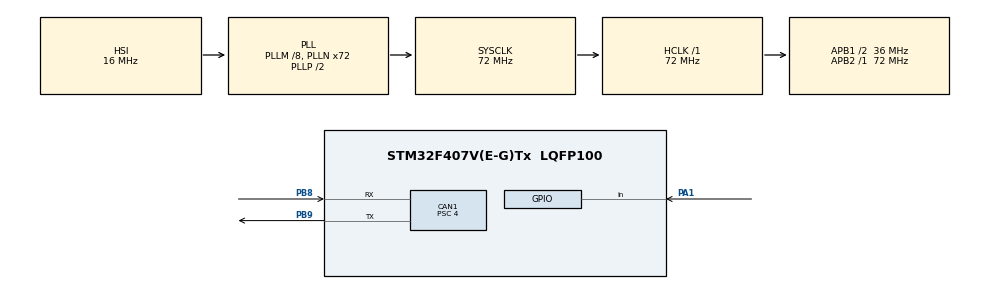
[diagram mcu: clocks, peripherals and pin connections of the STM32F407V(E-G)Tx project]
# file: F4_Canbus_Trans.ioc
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CAN1.BS1=CAN_BS1_15TQ
CAN1.BS2=CAN_BS2_2TQ
CAN1.CalculateBaudRate=500000
CAN1.CalculateTimeBit=2000
CAN1.CalculateTimeQuantum=111.11111111111111
CAN1.Prescaler=4
Mcu.Family=STM32F4
Mcu.Name=STM32F407V(E-G)Tx
Mcu.Package=LQFP100
NVIC.CAN1_RX0_IRQn=true\:1\:0\:true\:false\:true\:true\:true\:true
NVIC.PriorityGroup=NVIC_PRIORITYGROUP_4
PA1.GPIO_PuPd=GPIO_PULLUP
PA1.Signal=GPIO_Input
PA13.Mode=Serial_Wire
PA13.Signal=SYS_JTMS-SWDIO
PA14.Mode=Serial_Wire
PA14.Signal=SYS_JTCK-SWCLK
PB8.GPIO_PuPd=GPIO_PULLUP
PB8.Mode=CAN_Activate
PB8.Signal=CAN1_RX
PB9.Mode=CAN_Activate
PB9.Signal=CAN1_TX
PH0-OSC_IN.Mode=HSE-External-Oscillator
PH0-OSC_IN.Signal=RCC_OSC_IN
PH1-OSC_OUT.Mode=HSE-External-Oscillator
PH1-OSC_OUT.Signal=RCC_OSC_OUT
ProjectManager.HeapSize=0x200
ProjectManager.StackSize=0x400
ProjectManager.TargetToolchain=MDK-ARM V5.32
RCC.48MHZClocksFreq_Value=36000000
RCC.AHBFreq_Value=72000000
RCC.APB1CLKDivider=RCC_HCLK_DIV2
RCC.APB1Freq_Value=36000000
RCC.APB1TimFreq_Value=72000000
RCC.APB2Freq_Value=72000000
RCC.APB2TimFreq_Value=72000000
RCC.CortexFreq_Value=72000000
RCC.HCLKFreq_Value=72000000
RCC.HSE_VALUE=25000000
RCC.HSI_VALUE=16000000
RCC.LSE_VALUE=32768
RCC.PLLM=8
RCC.PLLN=72
RCC.SYSCLKFreq_VALUE=72000000
RCC.SYSCLKSource=RCC_SYSCLKSOURCE_PLLCLK
RCC.VCOOutputFreq_Value=144000000
board=custom

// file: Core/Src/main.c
/* USER CODE BEGIN Header */
/**
  ******************************************************************************
  * @file           : main.c
  * @brief          : Main program body
  ******************************************************************************
  * @attention
  *
  * Copyright (c) 2024 STMicroelectronics.
  * All rights reserved.
  *
  * This software is licensed under terms that can be found in the LICENSE file
  * in the root directory of this software component.
  * If no LICENSE file comes with this software, it is provided AS-IS.
  *
  ******************************************************************************
  */
/* USER CODE END Header */
#include "main.h"

/* USER CODE BEGIN Includes */
#include "Button.h"
#include "Rx.h"
#include "Tx.h"
/* USER CODE END Includes */

CAN_HandleTypeDef hcan1;

/* USER CODE BEGIN PV */
Button_TypeDef Button1;
/* USER CODE END PV */

void SystemClock_Config(void);
static void MX_GPIO_Init(void);
static void MX_CAN1_Init(void);

/* USER CODE BEGIN 0 */
CAN_TxHeaderTypeDef TxHeader;
uint8_t Tx[8];
uint32_t TxMailBox;
uint8_t test=0;
_LedState LedState = LedOff;
void button_press(Button_TypeDef *buttonx)//Ham xu li khi nhan nut
{
	if (buttonx == &Button1 )
	{
		switch(LedState)
		{
			case(LedOff):
				Tx[0]=1;
				LedState = LedBlink;
				break;
			case(LedBlink):
				Tx[0]=0;
				LedState = LedOff;
				break;
			default:
				break;
		}
		HAL_CAN_AddTxMessage(&hcan1,&TxHeader ,Tx,&TxMailBox );
	}
}
/* USER CODE END 0 */

int main(void)
{

  /* MCU Configuration--------------------------------------------------------*/

  /* Reset of all peripherals, Initializes the Flash interface and the Systick. */
  HAL_Init();

  /* Configure the system clock */
  SystemClock_Config();

  /* Initialize all configured peripherals */
  MX_GPIO_Init();
  MX_CAN1_Init();
  /* USER CODE BEGIN 2 */
	button_init(&Button1, GPIOA, GPIO_PIN_1);//Khai bao chan nut bam
	HAL_CAN_Start(&hcan1);
	//Config TxHeader
	TxHeader.DLC = 5;
	TxHeader.IDE = CAN_ID_STD;
	TxHeader.RTR = CAN_RTR_DATA;
	TxHeader.StdId = 0x222;
	TxHeader.TransmitGlobalTime = DISABLE;

	Tx_Data_Led_Blink(Tx,200);

	HAL_CAN_ActivateNotification(&hcan1,CAN_IT_RX_FIFO0_MSG_PENDING);
  /* USER CODE END 2 */

  /* Infinite loop */
  while (1)
  {

    /* USER CODE BEGIN 3 */
		button_handle(&Button1);
  }
  /* USER CODE END 3 */
}

void SystemClock_Config(void)
{
  RCC_OscInitTypeDef RCC_OscInitStruct = {0};
  RCC_ClkInitTypeDef RCC_ClkInitStruct = {0};

  /** Configure the main internal regulator output voltage
  */
  __HAL_RCC_PWR_CLK_ENABLE();
  __HAL_PWR_VOLTAGESCALING_CONFIG(PWR_REGULATOR_VOLTAGE_SCALE1);

  /** Initializes the RCC Oscillators according to the specified parameters
  * in the RCC_OscInitTypeDef structure.
  */
  RCC_OscInitStruct.OscillatorType = RCC_OSCILLATORTYPE_HSI;
  RCC_OscInitStruct.HSIState = RCC_HSI_ON;
  RCC_OscInitStruct.HSICalibrationValue = RCC_HSICALIBRATION_DEFAULT;
  RCC_OscInitStruct.PLL.PLLState = RCC_PLL_ON;
  RCC_OscInitStruct.PLL.PLLSource = RCC_PLLSOURCE_HSI;
  RCC_OscInitStruct.PLL.PLLM = 8;
  RCC_OscInitStruct.PLL.PLLN = 72;
  RCC_OscInitStruct.PLL.PLLP = RCC_PLLP_DIV2;
  RCC_OscInitStruct.PLL.PLLQ = 4;
  if (HAL_RCC_OscConfig(&RCC_OscInitStruct) != HAL_OK)
  {
    Error_Handler();
  }

  /** Initializes the CPU, AHB and APB buses clocks
  */
  RCC_ClkInitStruct.ClockType = RCC_CLOCKTYPE_HCLK|RCC_CLOCKTYPE_SYSCLK
                              |RCC_CLOCKTYPE_PCLK1|RCC_CLOCKTYPE_PCLK2;
  RCC_ClkInitStruct.SYSCLKSource = RCC_SYSCLKSOURCE_PLLCLK;
  RCC_ClkInitStruct.AHBCLKDivider = RCC_SYSCLK_DIV1;
  RCC_ClkInitStruct.APB1CLKDivider = RCC_HCLK_DIV2;
  RCC_ClkInitStruct.APB2CLKDivider = RCC_HCLK_DIV1;

  if (HAL_RCC_ClockConfig(&RCC_ClkInitStruct, FLASH_LATENCY_2) != HAL_OK)
  {
    Error_Handler();
  }
}

static void MX_CAN1_Init(void)
{

  hcan1.Instance = CAN1;
  hcan1.Init.Prescaler = 4;
  hcan1.Init.Mode = CAN_MODE_NORMAL;
  hcan1.Init.SyncJumpWidth = CAN_SJW_1TQ;
  hcan1.Init.TimeSeg1 = CAN_BS1_15TQ;
  hcan1.Init.TimeSeg2 = CAN_BS2_2TQ;
  hcan1.Init.TimeTriggeredMode = DISABLE;
  hcan1.Init.AutoBusOff = DISABLE;
  hcan1.Init.AutoWakeUp = DISABLE;
  hcan1.Init.AutoRetransmission = DISABLE;
  hcan1.Init.ReceiveFifoLocked = DISABLE;
  hcan1.Init.TransmitFifoPriority = DISABLE;
  if (HAL_CAN_Init(&hcan1) != HAL_OK)
  {
    Error_Handler();
  }
  /* USER CODE BEGIN CAN1_Init 2 */
	CAN_FilterTypeDef CanFilter;

	CanFilter.FilterActivation = CAN_FILTER_ENABLE;
	CanFilter.FilterBank = 10;
	CanFilter.FilterFIFOAssignment = CAN_FILTER_FIFO0;
	CanFilter.FilterIdHigh = 0X111<<5;
	CanFilter.FilterIdLow = 0X000000;
	CanFilter.FilterMaskIdHigh = 0X111<<5;
	CanFilter.FilterMaskIdLow = 0X000000;
	CanFilter.FilterMode = CAN_FILTERMODE_IDMASK;
	CanFilter.FilterScale = CAN_FILTERSCALE_32BIT;
	CanFilter.SlaveStartFilterBank = 0;

	HAL_CAN_ConfigFilter(&hcan1,&CanFilter);
  /* USER CODE END CAN1_Init 2 */

}

static void MX_GPIO_Init(void)
{
  GPIO_InitTypeDef GPIO_InitStruct = {0};

  /* GPIO Ports Clock Enable */
  __HAL_RCC_GPIOH_CLK_ENABLE();
  __HAL_RCC_GPIOA_CLK_ENABLE();
  __HAL_RCC_GPIOB_CLK_ENABLE();

  /*Configure GPIO pin : PA1 */
  GPIO_InitStruct.Pin = GPIO_PIN_1;
  GPIO_InitStruct.Mode = GPIO_MODE_INPUT;
  GPIO_InitStruct.Pull = GPIO_PULLUP;
  HAL_GPIO_Init(GPIOA, &GPIO_InitStruct);

}

void Error_Handler(void)
{
  __disable_irq();
  while (1)
  {
  }
}
